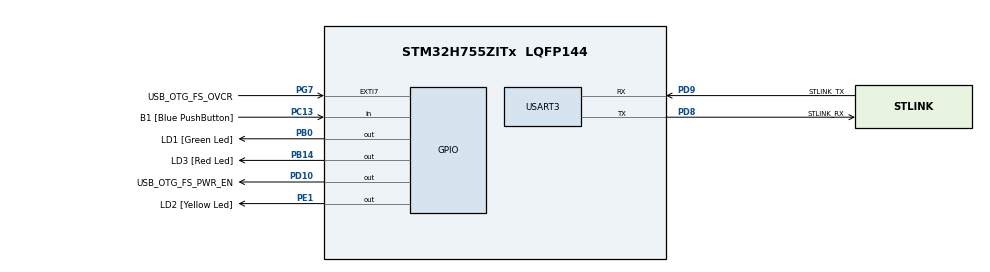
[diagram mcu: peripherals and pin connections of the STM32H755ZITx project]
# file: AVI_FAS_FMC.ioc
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CortexM4.IPs=FATFS_M4\:I,FREERTOS_M4\:I,IWDG2\:I,RCC,WWDG2\:I,DMA,BDMA,MDMA,NVIC2\:I,USART3,DEBUG,USB_DEVICE_M4\:I,USB_HOST_M4\:I,PDM2PCM_M4\:I,PWR,RESMGR_UTILITY,SYS_M4\:I,CORTEX_M4\:I,OPENAMP_M4\:I,VREFBUF,GPIO,TIM2\:I,I2C1\:I
CortexM4.Pins=PB14
CortexM7.IPs=FATFS_M7\:I,FREERTOS_M7\:I,IWDG1\:I,RCC\:I,WWDG1\:I,DMA\:I,BDMA\:I,MDMA\:I,NVIC1\:I,USART3\:I,SYS\:I,CORTEX_M7\:I,DEBUG\:I,USB_DEVICE_M7\:I,USB_HOST_M7\:I,PDM2PCM_M7\:I,PWR\:I,RESMGR_UTILITY\:I,OPENAMP_M7\:I,VREFBUF\:I,GPIO\:I,RTC\:I,TIM1\:I,I2C1
CortexM7.Pins=PB0
Dma.Request0=USART3_RX
Dma.Request1=USART3_TX
Dma.USART3_RX.0.Direction=DMA_PERIPH_TO_MEMORY
Dma.USART3_RX.0.EventEnable=DISABLE
Dma.USART3_RX.0.FIFOMode=DMA_FIFOMODE_DISABLE
Dma.USART3_RX.0.Instance=DMA1_Stream0
Dma.USART3_RX.0.MemDataAlignment=DMA_MDATAALIGN_BYTE
Dma.USART3_RX.0.MemInc=DMA_MINC_ENABLE
Dma.USART3_RX.0.Mode=DMA_NORMAL
Dma.USART3_RX.0.PeriphDataAlignment=DMA_PDATAALIGN_BYTE
Dma.USART3_RX.0.PeriphInc=DMA_PINC_DISABLE
Dma.USART3_RX.0.Polarity=HAL_DMAMUX_REQ_GEN_RISING
Dma.USART3_RX.0.Priority=DMA_PRIORITY_MEDIUM
Dma.USART3_RX.0.RequestNumber=1
Dma.USART3_RX.0.SignalID=NONE
Dma.USART3_RX.0.SyncEnable=DISABLE
Dma.USART3_RX.0.SyncPolarity=HAL_DMAMUX_SYNC_NO_EVENT
Dma.USART3_RX.0.SyncRequestNumber=1
Dma.USART3_RX.0.SyncSignalID=NONE
Dma.USART3_TX.1.Direction=DMA_MEMORY_TO_PERIPH
Dma.USART3_TX.1.EventEnable=DISABLE
Dma.USART3_TX.1.FIFOMode=DMA_FIFOMODE_DISABLE
Dma.USART3_TX.1.Instance=DMA1_Stream1
Dma.USART3_TX.1.MemDataAlignment=DMA_MDATAALIGN_BYTE
Dma.USART3_TX.1.MemInc=DMA_MINC_ENABLE
Dma.USART3_TX.1.Mode=DMA_NORMAL
Dma.USART3_TX.1.PeriphDataAlignment=DMA_PDATAALIGN_BYTE
Dma.USART3_TX.1.PeriphInc=DMA_PINC_DISABLE
Dma.USART3_TX.1.Polarity=HAL_DMAMUX_REQ_GEN_RISING
Dma.USART3_TX.1.Priority=DMA_PRIORITY_LOW
Dma.USART3_TX.1.RequestNumber=1
Dma.USART3_TX.1.SignalID=NONE
Dma.USART3_TX.1.SyncEnable=DISABLE
Dma.USART3_TX.1.SyncPolarity=HAL_DMAMUX_SYNC_NO_EVENT
Dma.USART3_TX.1.SyncRequestNumber=1
Dma.USART3_TX.1.SyncSignalID=NONE
FREERTOS_M4.Tasks01=CM4StatusLED,16,128,CM4StatusLEDTask,Default,NULL,Dynamic,NULL,NULL
FREERTOS_M7.Tasks01=CM7StatusLED,16,128,CM7StatusLEDTask,Default,NULL,Dynamic,NULL,NULL
Mcu.Family=STM32H7
Mcu.Name=STM32H755ZITx
Mcu.Package=LQFP144
NVIC1.DMA1_Stream0_IRQn=true\:5\:0\:false\:false\:true\:true\:false\:true\:true
NVIC1.DMA1_Stream1_IRQn=true\:5\:0\:false\:false\:true\:true\:false\:true\:true
NVIC1.PriorityGroup=NVIC_PRIORITYGROUP_4
NVIC1.TIM1_UP_IRQn=true\:15\:0\:false\:false\:true\:false\:false\:true\:true
NVIC1.TimeBase=TIM1_UP_IRQn
NVIC1.TimeBaseIP=TIM1
NVIC1.USART3_IRQn=true\:5\:0\:false\:false\:true\:true\:true\:true\:true
NVIC2.PriorityGroup=NVIC_PRIORITYGROUP_4
NVIC2.TIM2_IRQn=true\:15\:0\:false\:false\:true\:false\:false\:true\:true
NVIC2.TimeBase=TIM2_IRQn
NVIC2.TimeBaseIP=TIM2
PA1.PinAttribute=CortexM4
PA1.Signal=ETH_REF_CLK
PA11.PinAttribute=CortexM7
PA11.Signal=USB_OTG_FS_DM
PA12.PinAttribute=CortexM7
PA12.Signal=USB_OTG_FS_DP
PA2.PinAttribute=CortexM4
PA2.Signal=ETH_MDIO
PA7.PinAttribute=CortexM4
PA7.Signal=ETH_CRS_DV
PA8.PinAttribute=CortexM7
PA8.Signal=USB_OTG_FS_SOF
PA9.PinAttribute=CortexM7
PA9.Signal=USB_OTG_FS_VBUS
PB0.GPIO_Label=LD1 [Green Led]
PB0.PinAttribute=CortexM7
PB0.Signal=GPIO_Output
PB13.PinAttribute=CortexM4
PB13.Signal=ETH_TXD1
PB14.GPIO_Label=LD3 [Red Led]
PB14.PinAttribute=CortexM4
PB14.Signal=GPIO_Output
PC1.PinAttribute=CortexM4
PC1.Signal=ETH_MDC
PC13.GPIO_Label=B1 [Blue PushButton]
PC13.PinAttribute=Free
PC13.Signal=GPIO_Input
PC14-OSC32_IN\ (OSC32_IN).Mode=LSE-External-Oscillator
PC14-OSC32_IN\ (OSC32_IN).PinAttribute=CortexM7
PC14-OSC32_IN\ (OSC32_IN).Signal=RCC_OSC32_IN
PC15-OSC32_OUT\ (OSC32_OUT).Mode=LSE-External-Oscillator
PC15-OSC32_OUT\ (OSC32_OUT).PinAttribute=CortexM7
PC15-OSC32_OUT\ (OSC32_OUT).Signal=RCC_OSC32_OUT
PC4.PinAttribute=CortexM4
PC4.Signal=ETH_RXD0
PC5.PinAttribute=CortexM4
PC5.Signal=ETH_RXD1
PD10.GPIO_Label=USB_OTG_FS_PWR_EN
PD10.PinAttribute=Free
PD10.Signal=GPIO_Output
PD8.GPIO_Label=STLINK_RX
PD8.Mode=Asynchronous
PD8.PinAttribute=CortexM7
PD8.Signal=USART3_TX
PD9.GPIO_Label=STLINK_TX
PD9.Mode=Asynchronous
PD9.PinAttribute=CortexM7
PD9.Signal=USART3_RX
PE1.GPIO_Label=LD2 [Yellow Led]
PE1.PinAttribute=Free
PE1.Signal=GPIO_Output
PG11.PinAttribute=CortexM4
PG11.Signal=ETH_TX_EN
PG13.PinAttribute=CortexM4
PG13.Signal=ETH_TXD0
PG7.GPIO_Label=USB_OTG_FS_OVCR
PG7.PinAttribute=Free
PG7.Signal=GPXTI7
PH0-OSC_IN\ (PH0).Mode=HSE-External-Clock-Source
PH0-OSC_IN\ (PH0).PinAttribute=CortexM7
PH0-OSC_IN\ (PH0).Signal=RCC_OSC_IN
PH1-OSC_OUT\ (PH1).PinAttribute=CortexM7
PH1-OSC_OUT\ (PH1).Signal=RCC_OSC_OUT
ProjectManager.HeapSize=M4-0x200,M7-0x200
ProjectManager.StackSize=M4-0x400,M7-0x400
ProjectManager.TargetToolchain=Makefile
RCC.ADCFreq_Value=16125000
RCC.APB1Freq_Value=64000000
RCC.APB2Freq_Value=64000000
RCC.APB3Freq_Value=64000000
RCC.APB4Freq_Value=64000000
RCC.CortexFreq_Value=64000000
RCC.DIVM1=1
RCC.DIVN1=24
RCC.DIVQ1=4
RCC.HCLKFreq_Value=64000000
RCC.HSE_VALUE=8000000
RCC.PLL2FRACN=0
RCC.PLL3FRACN=0
RCC.PLLFRACN=0
RCC.PLLSourceVirtual=RCC_PLLSOURCE_HSE
RCC.PWR_Regulator_Voltage_Scale=PWR_REGULATOR_VOLTAGE_SCALE2
RCC.SYSCLKFreq_VALUE=64000000
RCC.SupplySource=PWR_DIRECT_SMPS_SUPPLY
RCC.USBCLockSelection=RCC_USBCLKSOURCE_PLL3
RCC.USBFreq_Value=16125000
RTC.Date=13
RTC.Month=RTC_MONTH_MARCH
RTC.Year=24
USART3.FIFOMode=FIFOMODE_DISABLE
USART3.RXFIFOThreshold=RXFIFO_THRESHOLD_HALFFULL
USART3.TXFIFOThreshold=TXFIFO_THRESHOLD_HALFFULL
USART3.VirtualMode-Asynchronous=VM_ASYNC
VP_FREERTOS_M4_VS_CMSIS_V2.Mode=CMSIS_V2
VP_FREERTOS_M7_VS_CMSIS_V2.Mode=CMSIS_V2
VP_RTC_VS_RTC_Activate.Mode=RTC_Enabled
VP_RTC_VS_RTC_Calendar.Mode=RTC_Calendar
VP_SYS_M4_VS_tim2.Mode=TIM2
VP_SYS_VS_tim1.Mode=TIM1
board=NUCLEO-H755ZI-Q

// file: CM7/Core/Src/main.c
/* USER CODE BEGIN Header */
/**
 ******************************************************************************
 * @file           : main.c
 * @brief          : Main program body
 ******************************************************************************
 * @attention
 *
 * Copyright (c) 2024 STMicroelectronics.
 * All rights reserved.
 *
 * This software is licensed under terms that can be found in the LICENSE file
 * in the root directory of this software component.
 * If no LICENSE file comes with this software, it is provided AS-IS.
 *
 ******************************************************************************
 */
/* USER CODE END Header */
#include "main.h"
#include "cmsis_os.h"

/* USER CODE BEGIN PD */

#ifndef HSEM_ID_0
#define HSEM_ID_0 (0U) /* HW semaphore 0*/
#endif

static unsigned int *test_ptr = (int *)0x38000000;

/* USER CODE END PD */

RTC_HandleTypeDef hrtc;

UART_HandleTypeDef huart3;
DMA_HandleTypeDef hdma_usart3_rx;
DMA_HandleTypeDef hdma_usart3_tx;

/* Definitions for CM7StatusLED */
osThreadId_t CM7StatusLEDHandle;
const osThreadAttr_t CM7StatusLED_attributes = {
    .name = "CM7StatusLED",
    .stack_size = 128 * 4,
    .priority = (osPriority_t)osPriorityBelowNormal,
};

void SystemClock_Config(void);
static void MX_GPIO_Init(void);
static void MX_DMA_Init(void);
static void MX_USART3_UART_Init(void);
static void MX_RTC_Init(void);
void CM7StatusLEDTask(void *argument);

int main(void)
{
  /* USER CODE BEGIN Boot_Mode_Sequence_0 */
  int32_t timeout;
  /* USER CODE END Boot_Mode_Sequence_0 */

  /* USER CODE BEGIN Boot_Mode_Sequence_1 */
  /* Wait until CPU2 boots and enters in stop mode or timeout*/
  timeout = 0xFFFF;
  while ((__HAL_RCC_GET_FLAG(RCC_FLAG_D2CKRDY) != RESET) && (timeout-- > 0))
    ;
  if (timeout < 0)
  {
    Error_Handler();
  }
  /* USER CODE END Boot_Mode_Sequence_1 */
  /* MCU Configuration--------------------------------------------------------*/

  /* Reset of all peripherals, Initializes the Flash interface and the Systick. */
  HAL_Init();

  /* Configure the system clock */
  SystemClock_Config();
  /* USER CODE BEGIN Boot_Mode_Sequence_2 */
  /* When system initialization is finished, Cortex-M7 will release Cortex-M4 by means of
  HSEM notification */
  /*HW semaphore Clock enable*/
  __HAL_RCC_HSEM_CLK_ENABLE();
  /*Take HSEM */
  HAL_HSEM_FastTake(HSEM_ID_0);
  /*Release HSEM in order to notify the CPU2(CM4)*/
  HAL_HSEM_Release(HSEM_ID_0, 0);
  /* wait until CPU2 wakes up from stop mode */
  timeout = 0xFFFF;
  while ((__HAL_RCC_GET_FLAG(RCC_FLAG_D2CKRDY) == RESET) && (timeout-- > 0))
    ;
  if (timeout < 0)
  {
    Error_Handler();
  }
  /* USER CODE END Boot_Mode_Sequence_2 */

  /* Initialize all configured peripherals */
  MX_GPIO_Init();
  MX_DMA_Init();
  MX_USART3_UART_Init();
  MX_RTC_Init();
  /* USER CODE BEGIN 2 */
  HAL_UART_Transmit_DMA(&huart3, (uint8_t *)"CORE 0: Initialization Complete...\n", 38);
  /* USER CODE END 2 */

  /* Init scheduler */
  osKernelInitialize();

  /* Create the thread(s) */
  /* creation of CM7StatusLED */
  CM7StatusLEDHandle = osThreadNew(CM7StatusLEDTask, NULL, &CM7StatusLED_attributes);

  /* Start scheduler */
  osKernelStart();

  /* We should never get here as control is now taken by the scheduler */
  /* Infinite loop */
  while (1)
  {

  }
}

void SystemClock_Config(void)
{
  RCC_OscInitTypeDef RCC_OscInitStruct = {0};
  RCC_ClkInitTypeDef RCC_ClkInitStruct = {0};

  /** Supply configuration update enable
   */
  HAL_PWREx_ConfigSupply(PWR_DIRECT_SMPS_SUPPLY);

  /** Configure the main internal regulator output voltage
   */
  __HAL_PWR_VOLTAGESCALING_CONFIG(PWR_REGULATOR_VOLTAGE_SCALE2);

  while (!__HAL_PWR_GET_FLAG(PWR_FLAG_VOSRDY))
  {
  }

  /** Initializes the RCC Oscillators according to the specified parameters
   * in the RCC_OscInitTypeDef structure.
   */
  RCC_OscInitStruct.OscillatorType = RCC_OSCILLATORTYPE_HSI | RCC_OSCILLATORTYPE_LSI;
  RCC_OscInitStruct.HSIState = RCC_HSI_DIV1;
  RCC_OscInitStruct.HSICalibrationValue = RCC_HSICALIBRATION_DEFAULT;
  RCC_OscInitStruct.LSIState = RCC_LSI_ON;
  RCC_OscInitStruct.PLL.PLLState = RCC_PLL_NONE;
  if (HAL_RCC_OscConfig(&RCC_OscInitStruct) != HAL_OK)
  {
    Error_Handler();
  }

  /** Initializes the CPU, AHB and APB buses clocks
   */
  RCC_ClkInitStruct.ClockType = RCC_CLOCKTYPE_HCLK | RCC_CLOCKTYPE_SYSCLK | RCC_CLOCKTYPE_PCLK1 | RCC_CLOCKTYPE_PCLK2 | RCC_CLOCKTYPE_D3PCLK1 | RCC_CLOCKTYPE_D1PCLK1;
  RCC_ClkInitStruct.SYSCLKSource = RCC_SYSCLKSOURCE_HSI;
  RCC_ClkInitStruct.SYSCLKDivider = RCC_SYSCLK_DIV1;
  RCC_ClkInitStruct.AHBCLKDivider = RCC_HCLK_DIV1;
  RCC_ClkInitStruct.APB3CLKDivider = RCC_APB3_DIV1;
  RCC_ClkInitStruct.APB1CLKDivider = RCC_APB1_DIV1;
  RCC_ClkInitStruct.APB2CLKDivider = RCC_APB2_DIV1;
  RCC_ClkInitStruct.APB4CLKDivider = RCC_APB4_DIV1;

  if (HAL_RCC_ClockConfig(&RCC_ClkInitStruct, FLASH_LATENCY_1) != HAL_OK)
  {
    Error_Handler();
  }
}

static void MX_RTC_Init(void)
{

  RTC_TimeTypeDef sTime = {0};
  RTC_DateTypeDef sDate = {0};

  /** Initialize RTC Only
   */
  hrtc.Instance = RTC;
  hrtc.Init.HourFormat = RTC_HOURFORMAT_24;
  hrtc.Init.AsynchPrediv = 127;
  hrtc.Init.SynchPrediv = 255;
  hrtc.Init.OutPut = RTC_OUTPUT_DISABLE;
  hrtc.Init.OutPutPolarity = RTC_OUTPUT_POLARITY_HIGH;
  hrtc.Init.OutPutType = RTC_OUTPUT_TYPE_OPENDRAIN;
  hrtc.Init.OutPutRemap = RTC_OUTPUT_REMAP_NONE;
  if (HAL_RTC_Init(&hrtc) != HAL_OK)
  {
    Error_Handler();
  }

  /** Initialize RTC and set the Time and Date
   */
  sTime.Hours = 0x0;
  sTime.Minutes = 0x0;
  sTime.Seconds = 0x0;
  sTime.DayLightSaving = RTC_DAYLIGHTSAVING_NONE;
  sTime.StoreOperation = RTC_STOREOPERATION_RESET;
  if (HAL_RTC_SetTime(&hrtc, &sTime, RTC_FORMAT_BCD) != HAL_OK)
  {
    Error_Handler();
  }
  sDate.WeekDay = RTC_WEEKDAY_MONDAY;
  sDate.Month = RTC_MONTH_MARCH;
  sDate.Date = 0x13;
  sDate.Year = 0x24;

  if (HAL_RTC_SetDate(&hrtc, &sDate, RTC_FORMAT_BCD) != HAL_OK)
  {
    Error_Handler();
  }
}

static void MX_USART3_UART_Init(void)
{

  huart3.Instance = USART3;
  huart3.Init.BaudRate = 115200;
  huart3.Init.WordLength = UART_WORDLENGTH_8B;
  huart3.Init.StopBits = UART_STOPBITS_1;
  huart3.Init.Parity = UART_PARITY_NONE;
  huart3.Init.Mode = UART_MODE_TX_RX;
  huart3.Init.HwFlowCtl = UART_HWCONTROL_NONE;
  huart3.Init.OverSampling = UART_OVERSAMPLING_16;
  huart3.Init.OneBitSampling = UART_ONE_BIT_SAMPLE_DISABLE;
  huart3.Init.ClockPrescaler = UART_PRESCALER_DIV1;
  huart3.AdvancedInit.AdvFeatureInit = UART_ADVFEATURE_NO_INIT;
  if (HAL_UART_Init(&huart3) != HAL_OK)
  {
    Error_Handler();
  }
  if (HAL_UARTEx_SetTxFifoThreshold(&huart3, UART_TXFIFO_THRESHOLD_1_2) != HAL_OK)
  {
    Error_Handler();
  }
  if (HAL_UARTEx_SetRxFifoThreshold(&huart3, UART_RXFIFO_THRESHOLD_1_2) != HAL_OK)
  {
    Error_Handler();
  }
  if (HAL_UARTEx_DisableFifoMode(&huart3) != HAL_OK)
  {
    Error_Handler();
  }
}

static void MX_DMA_Init(void)
{

  /* DMA controller clock enable */
  __HAL_RCC_DMA1_CLK_ENABLE();

  /* DMA interrupt init */
  /* DMA1_Stream0_IRQn interrupt configuration */
  HAL_NVIC_SetPriority(DMA1_Stream0_IRQn, 5, 0);
  HAL_NVIC_EnableIRQ(DMA1_Stream0_IRQn);
  /* DMA1_Stream1_IRQn interrupt configuration */
  HAL_NVIC_SetPriority(DMA1_Stream1_IRQn, 5, 0);
  HAL_NVIC_EnableIRQ(DMA1_Stream1_IRQn);
}

static void MX_GPIO_Init(void)
{
  GPIO_InitTypeDef GPIO_InitStruct = {0};

  /* GPIO Ports Clock Enable */
  __HAL_RCC_GPIOC_CLK_ENABLE();
  __HAL_RCC_GPIOH_CLK_ENABLE();
  __HAL_RCC_GPIOB_CLK_ENABLE();
  __HAL_RCC_GPIOD_CLK_ENABLE();

  /*Configure GPIO pin Output Level */
  HAL_GPIO_WritePin(LD1_GPIO_Port, LD1_Pin, GPIO_PIN_RESET);

  /*Configure GPIO pin : LD1_Pin */
  GPIO_InitStruct.Pin = LD1_Pin;
  GPIO_InitStruct.Mode = GPIO_MODE_OUTPUT_PP;
  GPIO_InitStruct.Pull = GPIO_NOPULL;
  GPIO_InitStruct.Speed = GPIO_SPEED_FREQ_LOW;
  HAL_GPIO_Init(LD1_GPIO_Port, &GPIO_InitStruct);

}

void CM7StatusLEDTask(void *argument)
{
  int num = 5;
  static uint8_t *test_ptr = (int *)0x38000000;

  /* USER CODE BEGIN 5 */
  /* Infinite loop */
  for (;;)
  {
    HAL_GPIO_TogglePin(LD1_GPIO_Port, LD1_Pin);

    HAL_UART_Transmit(&huart3, (uint8_t *)"Green:", 6, HAL_MAX_DELAY);
    osDelay(10);
    HAL_UART_Transmit(&huart3, (uint8_t *)test_ptr, 1, HAL_MAX_DELAY);
    osDelay(10);
    HAL_UART_Transmit(&huart3, (uint8_t *)"\n\n", 2, HAL_MAX_DELAY);
    osDelay(230);
  }
  /* USER CODE END 5 */
}

void HAL_TIM_PeriodElapsedCallback(TIM_HandleTypeDef *htim)
{
  if (htim->Instance == TIM1)
  {
    HAL_IncTick();
  }
}

void Error_Handler(void)
{
  __disable_irq();
  while (1)
  {
  }
}
